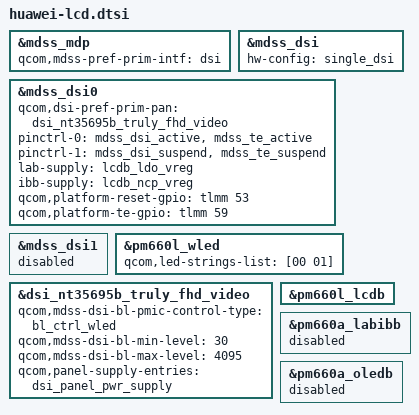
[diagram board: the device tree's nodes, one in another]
&mdss_mdp {
	qcom,mdss-pref-prim-intf = "dsi";
};

&mdss_dsi {
	hw-config = "single_dsi";
};

&mdss_dsi0 {
	qcom,dsi-pref-prim-pan = <&dsi_nt35695b_truly_fhd_video>;
	pinctrl-names = "mdss_default", "mdss_sleep";
	pinctrl-0 = <&mdss_dsi_active &mdss_te_active>;
	pinctrl-1 = <&mdss_dsi_suspend &mdss_te_suspend>;
	lab-supply = <&lcdb_ldo_vreg>;
	ibb-supply = <&lcdb_ncp_vreg>;
	qcom,platform-reset-gpio = <&tlmm 53 0>;
	qcom,platform-te-gpio = <&tlmm 59 0>;
};

&mdss_dsi1 {
	status = "disabled";
};

&pm660l_wled {
	qcom,led-strings-list = [00 01];
};

&dsi_nt35695b_truly_fhd_video {
	qcom,mdss-dsi-bl-pmic-control-type = "bl_ctrl_wled";
	qcom,mdss-dsi-bl-min-level = <30>;
	qcom,mdss-dsi-bl-max-level = <4095>;
	qcom,panel-supply-entries = <&dsi_panel_pwr_supply>;
};

&pm660l_wled {
	status = "ok";
};

&pm660l_lcdb {
    status = "ok";
};

&pm660a_labibb {
    status = "disabled";
};

&pm660a_oledb {
	status = "disabled";
};
